# MM32F103xx register map
File version: 1.08
Registers are 32-bit, read-write, reset 0x0 unless marked. A register's access mark holds for its fields unless they carry their own. Offsets are from the block's base; [hi:lo] are bit positions.

## RCC — Reset and clock control
Base 0x40021000
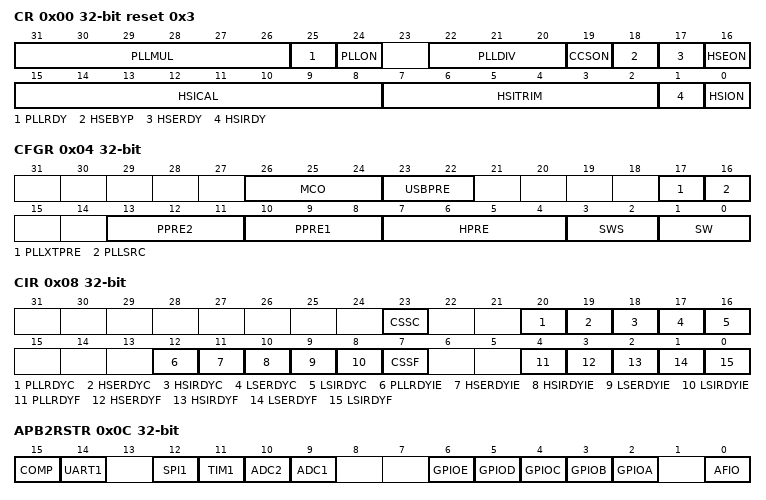
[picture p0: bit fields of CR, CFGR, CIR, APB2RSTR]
0x00 CR reset 0x3 — Control Register
  [31:26] PLLMUL — PLL divider factor
  [25] PLLRDY — PLL clock ready flag
  [24] PLLON — PLL enable
  [22:20] PLLDIV — PLL divider factor
  [19] CCSON — Clock security system enable
  [18] HSEBYP — External high-speed clock bypass
  [17] HSERDY — External high-speed clock ready flag
  [16] HSEON — External high-speed clock enable
  [15:8] HSICAL — *D8
  [7:2] HSITRIM — Internal High Speed clock trimming
  [1] HSIRDY — Internal high-speed clock ready flag
  [0] HSION — Internal high-speed clock enable
0x04 CFGR — Configuration Register
  [26:24] MCO — Microcontroller clock output
  [23:22] USBPRE — USB prescaler
  [17] PLLXTPRE — HSE divider for PLL entry
  [16] PLLSRC — PLL entry clock source
  [13:11] PPRE2 — APB high-speed prescaler(APB2)
  [10:8] PPRE1 — APB low-speed prescaler(APB1)
  [7:4] HPRE — AHB Prescaler
  [3:2] SWS — System clock switch status
  [1:0] SW — System clock switch
0x08 CIR — Clock Interrupt Register
  [23] CSSC — Clock security system interrupt clear
  [20] PLLRDYC — PLL ready interrupt clear
  [19] HSERDYC — HSE ready interrupt clear
  [18] HSIRDYC — HSI ready interrupt clear
  [17] LSERDYC — LSE ready interrupt clear
  [16] LSIRDYC — LSI ready interrupt clear
  [12] PLLRDYIE — PLL ready interrupt enable
  [11] HSERDYIE — HSE ready interrupt enable
  [10] HSIRDYIE — HSI ready interrupt enable
  [9] LSERDYIE — LSE ready interrupt enable
  [8] LSIRDYIE — LSI ready interrupt enable
  [7] CSSF — Clock security system interrupt flag
  [4] PLLRDYF — PLL ready interrupt flag
  [3] HSERDYF — HSE ready interrupt flag
  [2] HSIRDYF — HSI ready interrupt flag
  [1] LSERDYF — LSE ready interrupt flag
  [0] LSIRDYF — LSI ready interrupt flag
0x0C APB2RSTR — Advanced Peripheral Bus 2 Reset Register
  [15] COMP — COMP reset
  [14] UART1 — UART1 reset
  [12] SPI1 — SPI1 reset
  [11] TIM1 — TIM1 timer reset
  [10] ADC2 — ADC2 interface reset
  [9] ADC1 — ADC1 interface reset
  [6] GPIOE — I/O port E reset
  [5] GPIOD — I/O port D reset
  [4] GPIOC — I/O port C reset
  [3] GPIOB — I/O port B reset
  [2] GPIOA — I/O port A reset
  [0] AFIO — Alternate function I/O reset
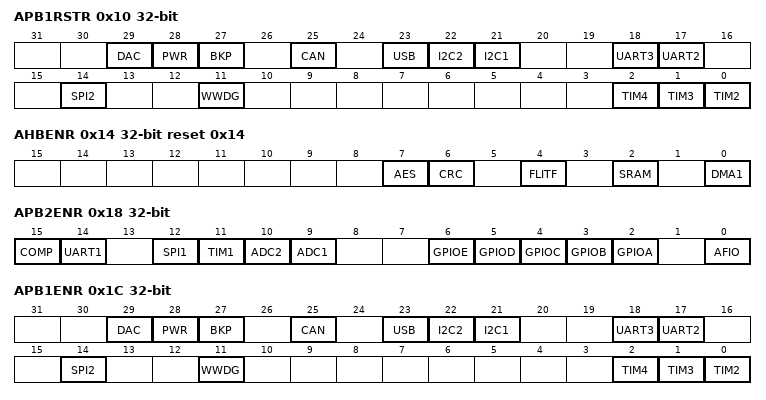
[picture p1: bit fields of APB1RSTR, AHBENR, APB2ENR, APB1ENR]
0x10 APB1RSTR — Advanced Peripheral Bus 1 Reset Register
  [29] DAC — DAC interface reset
  [28] PWR — Power interface reset
  [27] BKP — Backup interface reset
  [25] CAN — CAN reset
  [23] USB — USB reset
  [22] I2C2 — I2C2 reset
  [21] I2C1 — I2C1 reset
  [18] UART3 — UART3 reset
  [17] UART2 — UART2 reset
  [14] SPI2 — SPI2 reset
  [11] WWDG — Window watchdog reset
  [2] TIM4 — Timer 4 reset
  [1] TIM3 — Timer 3 reset
  [0] TIM2 — Timer 2 reset
0x14 AHBENR reset 0x14 — Advanced High Performance Bus Enable Register
  [7] AES — AES clock enable
  [6] CRC — CRC clock enable
  [4] FLITF — FLITF clock enable
  [2] SRAM — SRAM interface clock enable
  [0] DMA1 — DMA1 clock enable
0x18 APB2ENR — Advanced Peripheral Bus 2 Enable Register
  [15] COMP — COMP clock enable
  [14] UART1 — UART1 clock enable
  [12] SPI1 — SPI1 clock enable
  [11] TIM1 — TIM1 Timer clock enable
  [10] ADC2 — ADC2 interface clock enable
  [9] ADC1 — ADC1 interface clock enable
  [6] GPIOE — I/O port E clock enable
  [5] GPIOD — I/O port D clock enable
  [4] GPIOC — I/O port C clock enable
  [3] GPIOB — I/O port B clock enable
  [2] GPIOA — I/O port A clock enable
  [0] AFIO — Alternate function I/O clock enable
0x1C APB1ENR — Advanced Peripheral Bus 1 Enable Register
  [29] DAC — DAC interface clock enable
  [28] PWR — Power interface clock enable
  [27] BKP — Backup interface clock enable
  [25] CAN — CAN clock enable
  [23] USB — USB clock enable
  [22] I2C2 — I2C2 clock enable
  [21] I2C1 — I2C1 clock enable
  [18] UART3 — UART3 clock enable
  [17] UART2 — UART2 clock enable
  [14] SPI2 — SPI2 clock enable
  [11] WWDG — Window watchdog clock enable
  [2] TIM4 — Timer 4 clock enable
  [1] TIM3 — Timer 3 clock enable
  [0] TIM2 — Timer 2 clock enable
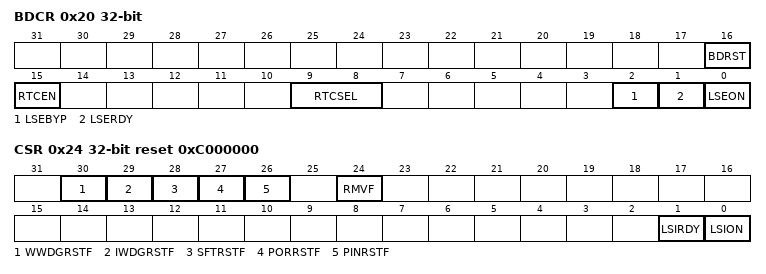
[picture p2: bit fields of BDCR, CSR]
0x20 BDCR — Backup Domain Control Register
  [16] BDRST — Backup domain software reset
  [15] RTCEN — RTC clock enable
  [9:8] RTCSEL — RTC clock source selection
  [2] LSEBYP — External low-speed oscillator bypass
  [1] LSERDY — External low-speed oscillator ready
  [0] LSEON — External low-speed oscillator enable
0x24 CSR reset 0xC000000 — Control Status Register
  [30] WWDGRSTF — Window watchdog reset flag
  [29] IWDGRSTF — Independent watchdog reset flag
  [28] SFTRSTF — Software reset flag
  [27] PORRSTF — POR/PDR reset flag
  [26] PINRSTF — PIN reset flag
  [24] RMVF — Remove reset flag
  [1] LSIRDY — Internal low-speed oscillator ready
  [0] LSION — Internal low-speed oscillator enable
0x40 SYSCGF — System Configuration Register
  [1] SYSCFG — *D1
